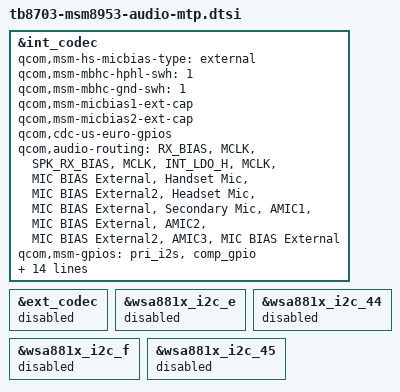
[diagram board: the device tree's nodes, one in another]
/*
 * Copyright (c) 2015-2016, The Linux Foundation. All rights reserved.
 *
 * This program is free software; you can redistribute it and/or modify
 * it under the terms of the GNU General Public License version 2 and
 * only version 2 as published by the Free Software Foundation.
 *
 * This program is distributed in the hope that it will be useful,
 * but WITHOUT ANY WARRANTY; without even the implied warranty of
 * MERCHANTABILITY or FITNESS FOR A PARTICULAR PURPOSE.  See the
 * GNU General Public License for more details.
 */

&int_codec {
	qcom,msm-hs-micbias-type = "external";
	qcom,msm-mbhc-hphl-swh = <1>;
	qcom,msm-mbhc-gnd-swh = <1>;
	qcom,msm-micbias1-ext-cap;
	qcom,msm-micbias2-ext-cap;
	qcom,cdc-us-euro-gpios;
	qcom,audio-routing =
			"RX_BIAS", "MCLK",
			"SPK_RX_BIAS", "MCLK",
			"INT_LDO_H", "MCLK",
			"MIC BIAS External", "Handset Mic",
			"MIC BIAS External2", "Headset Mic",
			"MIC BIAS External", "Secondary Mic",
			"AMIC1", "MIC BIAS External",
			"AMIC2", "MIC BIAS External2",
			"AMIC3", "MIC BIAS External";
	qcom,msm-gpios =
		"pri_i2s",
		"comp_gpio";

	qcom,pinctrl-names =
		"all_off",
		"pri_i2s_act",
		"comp_gpio_act",
		"comp_gpio_pri_i2s_act";

	pinctrl-names =
		"all_off",
		"pri_i2s_act",
		"comp_gpio_act",
		"comp_gpio_pri_i2s_act";

	pinctrl-0 = <&cdc_pdm_lines_sus &cdc_pdm_comp_lines_sus
		&cdc_pdm_lines_2_sus>;
	pinctrl-1 = <&cdc_pdm_lines_act &cdc_pdm_comp_lines_sus
		&cdc_pdm_lines_2_act>;
	pinctrl-2 = <&cdc_pdm_lines_sus &cdc_pdm_comp_lines_act
		&cdc_pdm_lines_2_sus>;
	pinctrl-3 = <&cdc_pdm_lines_act &cdc_pdm_comp_lines_act
		&cdc_pdm_lines_2_act>;
	qcom,spk_ext_pa_l = <&tlmm 6 0x0>;
	qcom,spk_ext_pa_r = <&tlmm 134 0x0>;
	qcom,spk_hs_switch = <&tlmm 91 0x0>;
	qcom,spk_rec_switch = <&tlmm 63 0x0>;
};

&ext_codec {
	status = "disabled";
};

&wsa881x_i2c_e {
	status = "disabled";
};

&wsa881x_i2c_44 {
	status = "disabled";
};

&wsa881x_i2c_f {
	status = "disabled";
};

&wsa881x_i2c_45 {
	status = "disabled";
};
